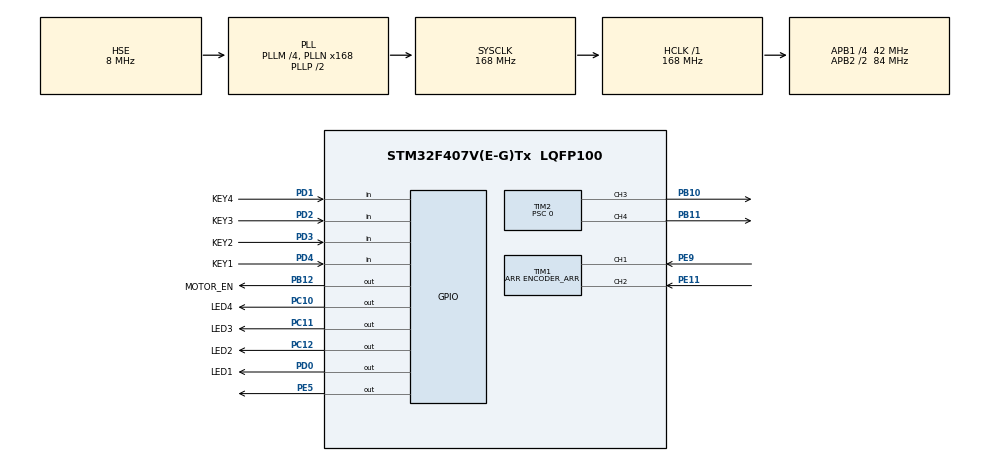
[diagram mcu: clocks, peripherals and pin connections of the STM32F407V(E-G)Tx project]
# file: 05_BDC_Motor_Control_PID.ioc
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Mcu.Family=STM32F4
Mcu.Name=STM32F407V(E-G)Tx
Mcu.Package=LQFP100
Mcu.UserConstants=PWM_ARR,2000 - 1;ENCODER_ARR,10000 - 1
NVIC.PriorityGroup=NVIC_PRIORITYGROUP_4
NVIC.TIM4_IRQn=true\:0\:0\:false\:false\:true\:true\:true\:true
PA13.Mode=Trace_Asynchronous_SW
PA13.Signal=SYS_JTMS-SWDIO
PA14.Mode=Trace_Asynchronous_SW
PA14.Signal=SYS_JTCK-SWCLK
PB10.Signal=S_TIM2_CH3
PB11.Signal=S_TIM2_CH4
PB12.GPIO_Label=MOTOR_EN
PB12.GPIO_Speed=GPIO_SPEED_FREQ_VERY_HIGH
PB12.Signal=GPIO_Output
PB3.Mode=Trace_Asynchronous_SW
PB3.Signal=SYS_JTDO-SWO
PC10.GPIO_Label=LED4
PC10.PinState=GPIO_PIN_SET
PC10.Signal=GPIO_Output
PC11.GPIO_Label=LED3
PC11.PinState=GPIO_PIN_SET
PC11.Signal=GPIO_Output
PC12.GPIO_Label=LED2
PC12.PinState=GPIO_PIN_SET
PC12.Signal=GPIO_Output
PD0.GPIO_Label=LED1
PD0.PinState=GPIO_PIN_SET
PD0.Signal=GPIO_Output
PD1.GPIO_Label=KEY4
PD1.GPIO_PuPd=GPIO_PULLUP
PD1.Signal=GPIO_Input
PD2.GPIO_Label=KEY3
PD2.GPIO_PuPd=GPIO_PULLUP
PD2.Signal=GPIO_Input
PD3.GPIO_Label=KEY2
PD3.GPIO_PuPd=GPIO_PULLUP
PD3.Signal=GPIO_Input
PD4.GPIO_Label=KEY1
PD4.GPIO_PuPd=GPIO_PULLUP
PD4.Signal=GPIO_Input
PE11.Signal=S_TIM1_CH2
PE5.PinState=GPIO_PIN_SET
PE5.Signal=GPIO_Output
PE9.Signal=S_TIM1_CH1
PH0-OSC_IN.Mode=HSE-External-Oscillator
PH0-OSC_IN.Signal=RCC_OSC_IN
PH1-OSC_OUT.Mode=HSE-External-Oscillator
PH1-OSC_OUT.Signal=RCC_OSC_OUT
ProjectManager.HeapSize=0x800
ProjectManager.StackSize=0x800
ProjectManager.TargetToolchain=MDK-ARM V5.32
RCC.48MHZClocksFreq_Value=84000000
RCC.AHBFreq_Value=168000000
RCC.APB1CLKDivider=RCC_HCLK_DIV4
RCC.APB1Freq_Value=42000000
RCC.APB1TimFreq_Value=84000000
RCC.APB2CLKDivider=RCC_HCLK_DIV2
RCC.APB2Freq_Value=84000000
RCC.APB2TimFreq_Value=168000000
RCC.CortexFreq_Value=168000000
RCC.HCLKFreq_Value=168000000
RCC.HSE_VALUE=8000000
RCC.HSI_VALUE=16000000
RCC.LSE_VALUE=32768
RCC.PLLM=4
RCC.PLLN=168
RCC.PLLSourceVirtual=RCC_PLLSOURCE_HSE
RCC.SYSCLKFreq_VALUE=168000000
RCC.SYSCLKSource=RCC_SYSCLKSOURCE_PLLCLK
RCC.VCOOutputFreq_Value=336000000
SH.S_TIM1_CH1.0=TIM1_CH1,Encoder_Interface
SH.S_TIM1_CH2.0=TIM1_CH2,Encoder_Interface
SH.S_TIM2_CH3.0=TIM2_CH3,PWM Generation3 CH3
SH.S_TIM2_CH4.0=TIM2_CH4,PWM Generation4 CH4
TIM1.EncoderMode=TIM_ENCODERMODE_TI12
TIM1.IC1Filter=10
TIM1.IC2Filter=10
TIM1.Period=ENCODER_ARR
TIM2.Channel-PWM\ Generation3\ CH3=TIM_CHANNEL_3
TIM2.Channel-PWM\ Generation4\ CH4=TIM_CHANNEL_4
TIM2.Period=PWM_ARR
TIM2.Prescaler=0
TIM4.Period=1000 - 1
TIM4.Prescaler=84 - 1
VP_TIM2_VS_ClockSourceINT.Mode=Internal
VP_TIM4_VS_ClockSourceINT.Mode=Internal
board=custom

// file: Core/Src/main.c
/* USER CODE BEGIN Header */
/**
  ******************************************************************************
  * @file           : main.c
  * @brief          : Main program body
  ******************************************************************************
  * @attention
  *
  * Copyright (c) 2023 STMicroelectronics.
  * All rights reserved.
  *
  * This software is licensed under terms that can be found in the LICENSE file
  * in the root directory of this software component.
  * If no LICENSE file comes with this software, it is provided AS-IS.
  *
  ******************************************************************************
  */
/* USER CODE END Header */
#include "main.h"
#include "tim.h"
#include "gpio.h"

void SystemClock_Config(void);
/* USER CODE BEGIN PFP */
extern void Setup(void);
extern void Loop(void);
/* USER CODE END PFP */

int main(void)
{

  /* MCU Configuration--------------------------------------------------------*/

  /* Reset of all peripherals, Initializes the Flash interface and the Systick. */
  HAL_Init();

  /* Configure the system clock */
  SystemClock_Config();

  /* Initialize all configured peripherals */
  MX_GPIO_Init();
  MX_TIM1_Init();
  MX_TIM2_Init();
  MX_TIM4_Init();
  /* USER CODE BEGIN 2 */
  Setup();
  /* USER CODE END 2 */

  /* Infinite loop */
  /* USER CODE BEGIN WHILE */
  while (1)
  {
    Loop();
    /* USER CODE END WHILE */

  }
}

void SystemClock_Config(void)
{
  RCC_OscInitTypeDef RCC_OscInitStruct = {0};
  RCC_ClkInitTypeDef RCC_ClkInitStruct = {0};

  /** Configure the main internal regulator output voltage
  */
  __HAL_RCC_PWR_CLK_ENABLE();
  __HAL_PWR_VOLTAGESCALING_CONFIG(PWR_REGULATOR_VOLTAGE_SCALE1);

  /** Initializes the RCC Oscillators according to the specified parameters
  * in the RCC_OscInitTypeDef structure.
  */
  RCC_OscInitStruct.OscillatorType = RCC_OSCILLATORTYPE_HSE;
  RCC_OscInitStruct.HSEState = RCC_HSE_ON;
  RCC_OscInitStruct.PLL.PLLState = RCC_PLL_ON;
  RCC_OscInitStruct.PLL.PLLSource = RCC_PLLSOURCE_HSE;
  RCC_OscInitStruct.PLL.PLLM = 4;
  RCC_OscInitStruct.PLL.PLLN = 168;
  RCC_OscInitStruct.PLL.PLLP = RCC_PLLP_DIV2;
  RCC_OscInitStruct.PLL.PLLQ = 4;
  if (HAL_RCC_OscConfig(&RCC_OscInitStruct) != HAL_OK)
  {
    Error_Handler();
  }

  /** Initializes the CPU, AHB and APB buses clocks
  */
  RCC_ClkInitStruct.ClockType = RCC_CLOCKTYPE_HCLK|RCC_CLOCKTYPE_SYSCLK
                              |RCC_CLOCKTYPE_PCLK1|RCC_CLOCKTYPE_PCLK2;
  RCC_ClkInitStruct.SYSCLKSource = RCC_SYSCLKSOURCE_PLLCLK;
  RCC_ClkInitStruct.AHBCLKDivider = RCC_SYSCLK_DIV1;
  RCC_ClkInitStruct.APB1CLKDivider = RCC_HCLK_DIV4;
  RCC_ClkInitStruct.APB2CLKDivider = RCC_HCLK_DIV2;

  if (HAL_RCC_ClockConfig(&RCC_ClkInitStruct, FLASH_LATENCY_5) != HAL_OK)
  {
    Error_Handler();
  }
}

void Error_Handler(void)
{
  __disable_irq();
  while (1)
  {
  }
}
